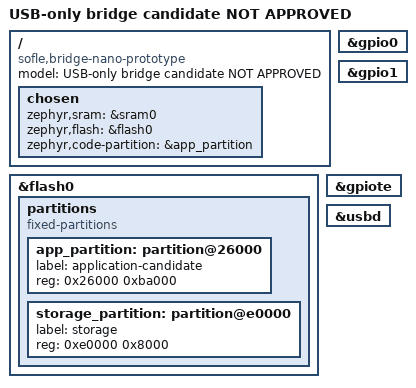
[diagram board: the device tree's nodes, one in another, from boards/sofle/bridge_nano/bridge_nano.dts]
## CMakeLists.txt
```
# Copyright (c) 2019 Nordic Semiconductor ASA
# SPDX-License-Identifier: LicenseRef-Nordic-5-Clause
cmake_minimum_required(VERSION 3.20.0)
set(BOARD_ROOT ${CMAKE_CURRENT_LIST_DIR})
find_package(Zephyr REQUIRED HINTS $ENV{ZEPHYR_BASE})
project(sofle_hogp_bridge)
target_sources(app PRIVATE src/main.c src/transport.c src/setup.c)
```

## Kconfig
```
# SPDX-License-Identifier: LicenseRef-Nordic-5-Clause
mainmenu "Sofle optional BLE HID host to USB bridge"
source "Kconfig.zephyr"
config BRIDGE_PHYSICAL_PAIRING
    bool "Unsupported physical pairing (negative-build safety gate only)"
    default n
    help
      No GPIO or reset button is assumed. Keep disabled. The USB vendor feature
      interface provides explicit scan/select/exact-target first pairing.
      Enabling physical pairing deliberately fails compilation even with alias.
config BRIDGE_AUTO_PAIR
    bool "Auto-pair to the exact keyboard name while the bond store is empty"
    default y
    help
      When the store has zero bonds, a connectable HID advertisement whose
      complete local name equals BRIDGE_PEER_NAME is connected and bonded
      automatically. The keyboard advertises this name only while a BT profile
      is in pairing mode, so first pairing needs no WebHID page. Any existing
      bond disables the path; re-pairing requires an explicit SETUP_UNBOND.
config BRIDGE_PEER_NAME
    string "Exact complete local name of the keyboard"
    default "Sofle_Oled"
    depends on BRIDGE_AUTO_PAIR
```

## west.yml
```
manifest:
  version: "0.13"
  projects:
    - name: nrf
      url: https://github.com/nrfconnect/sdk-nrf
      revision: 6961c01f95c2ec9f0f61870b68904bd398811f49 # NCS v2.9.3
      import:
        name-allowlist:
          - zephyr
          - cmsis
          - hal_nordic
          - segger
          - tinycrypt
          - nrfxlib
          - mbedtls
          - oberon-psa-crypto
          - zcbor
  self:
    path: bridge-manifest
```

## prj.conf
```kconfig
# Derived from roBa m1-hogp; SPDX-License-Identifier: LicenseRef-Nordic-5-Clause
CONFIG_BT=y
CONFIG_BT_CENTRAL=y
CONFIG_BT_CTLR=y
CONFIG_BT_LL_SOFTDEVICE=y
CONFIG_BT_SMP=y
CONFIG_BT_BONDABLE=n
CONFIG_BT_SMP_APP_PAIRING_ACCEPT=y
CONFIG_BT_GATT_CLIENT=y
CONFIG_BT_GATT_DM=y
CONFIG_BT_HOGP=y
CONFIG_BT_SCAN=y
CONFIG_BT_SCAN_FILTER_ENABLE=y
CONFIG_BT_SCAN_UUID_CNT=1
CONFIG_BT_PRIVACY=y
CONFIG_BT_SETTINGS=y
CONFIG_BT_MAX_CONN=1
CONFIG_BT_MAX_PAIRED=1
CONFIG_BT_KEYS_OVERWRITE_OLDEST=n
CONFIG_BT_ATT_TX_COUNT=5
CONFIG_BT_GATT_DM_MAX_ATTRS=100
CONFIG_BT_HOGP_REPORTS_MAX=8
# Peripheral-only auto-update Kconfig is inapplicable here; le_param_req accepts PPCP.
CONFIG_BT_GAP_AUTO_UPDATE_CONN_PARAMS=n
CONFIG_BT_USER_PHY_UPDATE=n
CONFIG_BT_AUTO_PHY_UPDATE=n
CONFIG_BT_DEVICE_NAME="Sofle optional HID bridge"
CONFIG_BT_CTLR_TX_PWR_PLUS_8=y
CONFIG_SYSTEM_WORKQUEUE_STACK_SIZE=4096
CONFIG_MAIN_STACK_SIZE=2048
CONFIG_HEAP_MEM_POOL_SIZE=4096
CONFIG_FLASH=y
CONFIG_FLASH_PAGE_LAYOUT=y
CONFIG_FLASH_MAP=y
CONFIG_NVS=y
CONFIG_SETTINGS=y
CONFIG_SETTINGS_NVS=y
CONFIG_USB_DEVICE_STACK=y
CONFIG_USB_COMPOSITE_DEVICE=y
CONFIG_USB_DEVICE_INITIALIZE_AT_BOOT=n
CONFIG_USB_DEVICE_HID=y
CONFIG_USB_HID_DEVICE_COUNT=2
CONFIG_ENABLE_HID_INT_OUT_EP=n
CONFIG_HID_INTERRUPT_EP_MPS=16
CONFIG_USB_HID_POLL_INTERVAL_MS=1
CONFIG_USB_HID_BOOT_PROTOCOL=n
CONFIG_USB_DEVICE_MANUFACTURER="Sofle bridge prototype"
CONFIG_USB_DEVICE_PRODUCT="Sofle BLE HID bridge NOT APPROVED"
CONFIG_USB_DEVICE_VID=0x2FE3
CONFIG_USB_DEVICE_PID=0x0100
CONFIG_USB_SELF_POWERED=n
CONFIG_LOG=n
CONFIG_BOOT_BANNER=n
CONFIG_NCS_BOOT_BANNER=n
CONFIG_PRINTK=n
CONFIG_CONSOLE=n
CONFIG_SERIAL=n
CONFIG_REBOOT=n
CONFIG_GPIO=y
CONFIG_USE_DT_CODE_PARTITION=y
CONFIG_BUILD_OUTPUT_HEX=y
CONFIG_BUILD_OUTPUT_BIN=y
CONFIG_BUILD_OUTPUT_UF2=n

# Auto-pairing to the keyboard while the bond store is empty.
CONFIG_BRIDGE_AUTO_PAIR=y
CONFIG_BRIDGE_PEER_NAME="Sofle_Oled"
```

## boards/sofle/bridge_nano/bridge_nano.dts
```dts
/* SPDX-License-Identifier: MIT
 * Compile-only candidate. NOT an approved flash layout. No UICR/regulator writes.
 * 0x26000 is the observed third-controller application's vector address.
 * Settings location is a NEW conservative candidate, not inferred from CURRENT.UF2.
 */
/dts-v1/;
#include <nordic/nrf52840_qiaa.dtsi>
/ {
    model = "USB-only bridge candidate NOT APPROVED";
    compatible = "sofle,bridge-nano-prototype";
    chosen {
        zephyr,sram = &sram0;
        zephyr,flash = &flash0;
        zephyr,code-partition = &app_partition;
    };
};
&flash0 {
    partitions {
        compatible = "fixed-partitions";
        #address-cells = <1>;
        #size-cells = <1>;
        app_partition: partition@26000 {
            label = "application-candidate";
            reg = <0x26000 0xba000>;
        };
        storage_partition: partition@e0000 {
            label = "storage";
            reg = <0xe0000 0x8000>;
        };
    };
};
&gpio0 { status = "okay"; };
&gpio1 { status = "okay"; };
&gpiote { status = "okay"; };
zephyr_udc0: &usbd { status = "okay"; };
```

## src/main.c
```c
/* main.c - adapted from hirosatosou/roba-ble-hid-bridge m1-hogp
 * Copyright (c) 2018 Nordic Semiconductor ASA
 * SPDX-License-Identifier: LicenseRef-Nordic-5-Clause
 * Nordic nRF52840 only. See UPSTREAM.md for provenance and deliberate removals.
 */
#include <errno.h>
#include <string.h>
#include <zephyr/kernel.h>
#include <zephyr/device.h>
#include <zephyr/drivers/gpio.h>
#include <zephyr/usb/usb_device.h>
#include <zephyr/usb/class/usb_hid.h>
#include <zephyr/bluetooth/bluetooth.h>
#include <zephyr/bluetooth/hci.h>
#include <zephyr/bluetooth/conn.h>
#include <zephyr/bluetooth/uuid.h>
#include <zephyr/bluetooth/gatt.h>
#include <zephyr/settings/settings.h>
#include <bluetooth/gatt_dm.h>
#include <bluetooth/scan.h>
#include <bluetooth/services/hogp.h>
#include "transport.h"
#include "setup.h"
#include "zmk_descriptor.h"

static struct bt_conn *default_conn;
static struct bt_hogp hogp;
static const struct device *hid_dev;
static struct bridge_queue queue;
static struct bridge_item in_flight; /* never alias a ring slot while USB owns it */
static bool ep_in_flight, usb_configured;
static atomic_t map_verified;
static struct k_spinlock hid_lock;
static struct setup_state setup;
static struct k_spinlock setup_lock;
static atomic_t conn_pending, have_bond, auto_pairing;
static bt_addr_le_t auto_target; /* exact-name auto-pair candidate in progress */
static bool auto_name_match; /* valid for the advertisement being processed */
static uint8_t feature_reply[SETUP_WIRE_SIZE];
static bool target_allowed(const bt_addr_le_t *addr) {
    k_spinlock_key_t key = k_spin_lock(&setup_lock);
    bool allowed = setup_target_allowed(&setup, k_uptime_get(), addr->type, addr->a.val);
    k_spin_unlock(&setup_lock, key);
    return allowed;
}
static void setup_end(void) {
    k_spinlock_key_t key = k_spin_lock(&setup_lock);
    setup_close(&setup);
    k_spin_unlock(&setup_lock, key);
    bt_set_bondable(false);
}
static size_t map_offset;
static uint8_t report_mask;

struct bond_lookup { const bt_addr_le_t *addr; bool found; };
static void bond_lookup_cb(const struct bt_bond_info *info, void *user_data) {
    struct bond_lookup *lookup = user_data;
    if (bt_addr_le_eq(&info->addr, lookup->addr)) lookup->found = true;
}
static bool is_bonded(const bt_addr_le_t *addr) {
    struct bond_lookup lookup = { .addr = addr };
    bt_foreach_bond(BT_ID_DEFAULT, bond_lookup_cb, &lookup);
    return lookup.found;
}
static void bond_count_cb(const struct bt_bond_info *info, void *user_data) {
    ARG_UNUSED(info); ++*(unsigned *)user_data;
}
static bool any_bond(void) {
    unsigned count = 0;
    bt_foreach_bond(BT_ID_DEFAULT, bond_count_cb, &count);
    return count != 0;
}
/* Called with hid_lock. A failed write keeps the item for periodic retry. */
static void hid_pump(void) {
    if (!usb_configured || ep_in_flight || queue.head == queue.tail) return;
    in_flight = queue.items[queue.tail];
    if (!hid_int_ep_write(hid_dev, in_flight.buf, in_flight.len, NULL)) {
        ep_in_flight = true;
        queue.tail = (queue.tail + 1) % BRIDGE_QUEUE_LEN;
    }
}
static void release_all(void) {
    k_spinlock_key_t key = k_spin_lock(&hid_lock);
    bridge_release_all(&queue);
    hid_pump();
    k_spin_unlock(&hid_lock, key);
}
static void hid_in_ready(const struct device *dev) {
    ARG_UNUSED(dev);
    k_spinlock_key_t key = k_spin_lock(&hid_lock);
    ep_in_flight = false;
    hid_pump();
    k_spin_unlock(&hid_lock, key);
}
static const struct hid_ops hid_ops = { .int_in_ready = hid_in_ready };
static void scan_restart(void);
static void unbond_work_fn(struct k_work *work) {
    ARG_UNUSED(work);
    (void)bt_unpair(BT_ID_DEFAULT, NULL); /* clear the whole store for this ID */
    atomic_clear(&have_bond);
    scan_restart(); /* bond store empty: auto-pair may run again */
}
static K_WORK_DEFINE(unbond_work, unbond_work_fn);
static int feature_set(const struct device *dev, struct usb_setup_packet *packet,
                       int32_t *len, uint8_t **data) {
    ARG_UNUSED(dev);
    if (!len || !data || *len < 0) return -EINVAL;
    k_spinlock_key_t key = k_spin_lock(&setup_lock);
    bool ok = setup_feature_set(&setup, k_uptime_get(), atomic_get(&conn_pending),
                               atomic_get(&have_bond), packet->wValue, packet->wLength,
                               *data, (size_t)*len);
    /* op byte sits at data[2]; SETUP_OK at reply[3]. The unpair itself is
     * deferred out of the USB callback context. */
    if (ok && (*data)[2] == SETUP_UNBOND && setup.reply[3] == SETUP_OK)
        k_work_submit(&unbond_work);
    k_spin_unlock(&setup_lock, key);
    return ok ? 0 : -EINVAL;
}
static int feature_get(const struct device *dev, struct usb_setup_packet *packet,
                       int32_t *len, uint8_t **data) {
    ARG_UNUSED(dev);
    if (!setup_feature_get_valid(packet->wValue, packet->wLength)) return -EINVAL;
    k_spinlock_key_t key = k_spin_lock(&setup_lock);
    memcpy(feature_reply, setup.reply, sizeof(feature_reply));
    k_spin_unlock(&setup_lock, key);
    *data = feature_reply; *len = sizeof(feature_reply);
    return 0;
}
static const struct hid_ops setup_ops = { .get_report = feature_get, .set_report = feature_set };
static void usb_status(enum usb_dc_status_code status, const uint8_t *param) {
    ARG_UNUSED(param);
    if (status == USB_DC_DISCONNECTED || status == USB_DC_RESET || status == USB_DC_SUSPEND) {
        k_spinlock_key_t sk = k_spin_lock(&setup_lock);
        setup_close(&setup); /* no pairing permission survives USB loss */
        k_spin_unlock(&setup_lock, sk);
    }
    k_spinlock_key_t key = k_spin_lock(&hid_lock);
    if (status == USB_DC_CONFIGURED) {
        usb_configured = true;
        ep_in_flight = false;
        bridge_release_all(&queue);
    } else if (status == USB_DC_DISCONNECTED || status == USB_DC_RESET) {
        usb_configured = false;
        ep_in_flight = false;
        bridge_release_all(&queue);
    }
    k_spin_unlock(&hid_lock, key);
}

static void scan_restart_work_fn(struct k_work *work) {
    ARG_UNUSED(work);
    if (default_conn) return;
    (void)bt_scan_stop();
    (void)bt_scan_start(BT_SCAN_TYPE_SCAN_ACTIVE);
}
static K_WORK_DELAYABLE_DEFINE(scan_restart_work, scan_restart_work_fn);
static void scan_restart(void) {
    k_work_reschedule(&scan_restart_work, K_SECONDS(1));
}
#if defined(CONFIG_BRIDGE_PHYSICAL_PAIRING)
/* Retain the negative build gate; no physical pairing path is implemented. */
BUILD_ASSERT(DT_NODE_HAS_STATUS(DT_ALIAS(bridge_pair), okay),
             "Verify physical wiring and define bridge-pair; never guess a GPIO");
BUILD_ASSERT(0, "Physical pairing unavailable: use explicit USB target selection");
#endif

/* Unlike upstream connect_if_match=1, unknown HID advertisements cannot create
 * connections outside an explicit window. Resolved bonded identity is allowed.
 */
static void try_connect(struct bt_scan_device_info *device_info, bool connectable) {
    if (!connectable || default_conn) return;
    const bt_addr_le_t *addr = device_info->recv_info->addr;
    bool bonded = is_bonded(addr);
    if (!bonded) {
        bool allowed = false;
        /* Auto-pair: ONLY when the store has zero bonds and the advertiser's
         * exact complete name equals CONFIG_BRIDGE_PEER_NAME. The keyboard
         * advertises this way only while a profile is in pairing mode, so a
         * bare dongle in a USB port pairs by plugging, with no WebHID page.
         * Any bond (even a foreign one) disables the path entirely. */
        if (IS_ENABLED(CONFIG_BRIDGE_AUTO_PAIR) && !any_bond() && auto_name_match) {
            atomic_set(&auto_pairing, 1);
            auto_target = *addr;
            allowed = true;
        } else {
            k_spinlock_key_t key = k_spin_lock(&setup_lock);
            allowed = setup_claim(&setup, k_uptime_get(), addr->type, addr->a.val);
            k_spin_unlock(&setup_lock, key);
        }
        if (!allowed) return;
        /* Set bondable before create/security, never from the USB callback. */
        bt_set_bondable(true);
    }
    if (bt_scan_stop()) {
        if (!bonded) { atomic_clear(&auto_pairing); setup_end(); }
        return;
    }
    atomic_set(&conn_pending, 1);
    struct bt_conn *conn = NULL;
    int err = bt_conn_le_create(device_info->recv_info->addr, BT_CONN_LE_CREATE_CONN,
                                BT_LE_CONN_PARAM(6, 24, 30, 400), &conn);
    if (!err) default_conn = conn; /* retain create's reference, released on disconnect */
    else { atomic_clear(&conn_pending); if (!bonded) { atomic_clear(&auto_pairing); setup_end(); } scan_restart(); }
}
static bool candidate_name(struct bt_data *data, void *user_data) {
    struct setup_peer *peer = user_data;
    if (data->type == BT_DATA_NAME_COMPLETE || data->type == BT_DATA_NAME_SHORTENED) {
        memcpy(peer->name, data->data, MIN(data->data_len, sizeof(peer->name) - 1));
        peer->name[sizeof(peer->name) - 1] = '\0';
        auto_name_match = IS_ENABLED(CONFIG_BRIDGE_AUTO_PAIR) &&
            strcmp(peer->name, CONFIG_BRIDGE_PEER_NAME) == 0;
        return false;
    }
    return true;
}
static void scan_filter_match(struct bt_scan_device_info *device_info,
                              struct bt_scan_filter_match *filter_match, bool connectable) {
    if (filter_match->uuid.match) {
        if (connectable) {
            struct setup_peer peer = { .type = device_info->recv_info->addr->type,
                                      .rssi = device_info->recv_info->rssi };
            memcpy(peer.addr, device_info->recv_info->addr->a.val, 6);
            auto_name_match = false;
            bt_data_parse(device_info->adv_data, candidate_name, &peer);
            k_spinlock_key_t key = k_spin_lock(&setup_lock);
            setup_observe(&setup, k_uptime_get(), &peer);
            k_spin_unlock(&setup_lock, key);
        }
        try_connect(device_info, connectable);
    }
}
static void scan_filter_no_match(struct bt_scan_device_info *device_info, bool connectable) {
    /* Directed reconnect often omits the HID service UUID. Bond check is mandatory. */
    if (device_info->recv_info->adv_type == BT_GAP_ADV_TYPE_ADV_DIRECT_IND &&
        is_bonded(device_info->recv_info->addr)) try_connect(device_info, connectable);
}
BT_SCAN_CB_INIT(scan_cb, scan_filter_match, scan_filter_no_match, NULL, NULL);
static int scan_init(void) {
    struct bt_scan_init_param init = { .connect_if_match = 0 };
    bt_scan_init(&init);
    bt_scan_cb_register(&scan_cb);
    int err = bt_scan_filter_add(BT_SCAN_FILTER_TYPE_UUID, BT_UUID_HIDS);
    if (err) return err;
    return bt_scan_filter_enable(BT_SCAN_UUID_FILTER, false);
}

static void discovery_completed_cb(struct bt_gatt_dm *dm, void *context) {
    ARG_UNUSED(context);
    int err = bt_hogp_handles_assign(dm, &hogp);
    (void)bt_gatt_dm_data_release(dm);
    if (err && default_conn)
        (void)bt_conn_disconnect(default_conn, BT_HCI_ERR_REMOTE_USER_TERM_CONN);
}
static void discovery_service_not_found_cb(struct bt_conn *conn, void *context) {
    ARG_UNUSED(context);
    (void)bt_conn_disconnect(conn, BT_HCI_ERR_REMOTE_USER_TERM_CONN);
}
static void discovery_error_found_cb(struct bt_conn *conn, int err, void *context) {
    ARG_UNUSED(err); discovery_service_not_found_cb(conn, context);
}
static const struct bt_gatt_dm_cb discovery_cb = {
    .completed = discovery_completed_cb,
    .service_not_found = discovery_service_not_found_cb,
    .error_found = discovery_error_found_cb,
};
static void connected(struct bt_conn *conn, uint8_t conn_err) {
    if (conn_err) {
        if (default_conn == conn) { bt_conn_unref(default_conn); default_conn = NULL; }
        atomic_clear(&conn_pending); setup_end(); scan_restart(); return;
    }
    if (!is_bonded(bt_conn_get_dst(conn)) && !target_allowed(bt_conn_get_dst(conn)) &&
        !(atomic_get(&auto_pairing) && bt_addr_le_eq(bt_conn_get_dst(conn), &auto_target))) {
        (void)bt_conn_disconnect(conn, BT_HCI_ERR_REMOTE_USER_TERM_CONN); return;
    }
    /* Do not force 2M; Sofle EXPERIMENTAL_CONN explicitly disables it.
     * Do not reject the keyboard's latency or keep reasserting min interval. */
    if (bt_conn_set_security(conn, BT_SECURITY_L2))
        (void)bt_conn_disconnect(conn, BT_HCI_ERR_AUTH_FAIL);
}
static void disconnected(struct bt_conn *conn, uint8_t reason) {
    ARG_UNUSED(reason);
    if (default_conn != conn) return;
    atomic_clear(&map_verified);
    release_all();
    if (bt_hogp_assign_check(&hogp)) bt_hogp_release(&hogp);
    bt_conn_unref(default_conn);
    default_conn = NULL;
    atomic_clear(&conn_pending); atomic_clear(&auto_pairing); setup_end();
    scan_restart(); /* keeps bonds; never unpair on RF/authentication failure */
}
static void security_changed(struct bt_conn *conn, bt_security_t level, enum bt_security_err err) {
    if (conn != default_conn) return;
    if (err || level < BT_SECURITY_L2 ||
        (!is_bonded(bt_conn_get_dst(conn)) && !target_allowed(bt_conn_get_dst(conn)))) {
        (void)bt_conn_disconnect(conn, BT_HCI_ERR_AUTH_FAIL); return;
    }
    if (bt_gatt_dm_start(conn, BT_UUID_HIDS, &discovery_cb, NULL))
        (void)bt_conn_disconnect(conn, BT_HCI_ERR_REMOTE_USER_TERM_CONN);
}
static bool le_param_req(struct bt_conn *conn, struct bt_le_conn_param *param) {
    ARG_UNUSED(conn); ARG_UNUSED(param);
    return true; /* let the controller validate spec bounds; accept Sofle PPCP */
}
BT_CONN_CB_DEFINE(conn_callbacks) = {
    .connected = connected, .disconnected = disconnected,
    .security_changed = security_changed, .le_param_req = le_param_req,
};
static enum bt_security_err pairing_accept(struct bt_conn *conn,
                                           const struct bt_conn_pairing_feat *feat) {
    ARG_UNUSED(feat);
    /* Existing bonds may encrypt/reconnect, but SMP re-pair/replacement is denied. */
    return conn == default_conn && !is_bonded(bt_conn_get_dst(conn)) &&
           (target_allowed(bt_conn_get_dst(conn)) ||
            (atomic_get(&auto_pairing) &&
             bt_addr_le_eq(bt_conn_get_dst(conn), &auto_target)))
        ? BT_SECURITY_ERR_SUCCESS : BT_SECURITY_ERR_PAIR_NOT_ALLOWED;
}
static const struct bt_conn_auth_cb auth_callbacks = { .pairing_accept = pairing_accept };
static void pairing_complete(struct bt_conn *conn, bool bonded) {
    if (!bonded) { (void)bt_conn_disconnect(conn, BT_HCI_ERR_AUTH_FAIL); return; }
    atomic_set(&have_bond, 1);
    atomic_clear(&auto_pairing);
    setup_end();
}
static struct bt_conn_auth_info_cb auth_info = { .pairing_complete = pairing_complete };

static uint8_t hogp_notify_cb(struct bt_hogp *client, struct bt_hogp_rep_info *rep,
                              uint8_t err, const uint8_t *data) {
    ARG_UNUSED(client);
    if (!data) return BT_GATT_ITER_STOP;
    if (err || !atomic_get(&map_verified)) return BT_GATT_ITER_CONTINUE;
    struct bridge_item item;
    /* Report Reference determines ID and TYPE; NOT enumeration order/handle.
     * Only the body is provided by HOGP; append exactly one USB report ID. */
    if (!bridge_convert(&item, bt_hogp_rep_id(rep), bt_hogp_rep_type(rep),
                        data, bt_hogp_rep_size(rep))) return BT_GATT_ITER_CONTINUE;
    k_spinlock_key_t key = k_spin_lock(&hid_lock);
    (void)bridge_enqueue(&queue, &item);
    hid_pump();
    k_spin_unlock(&hid_lock, key);
    return BT_GATT_ITER_CONTINUE;
}
static void subscribe_work_fn(struct k_work *work) {
    ARG_UNUSED(work);
    if (!default_conn || !bt_hogp_assign_check(&hogp) || !atomic_get(&map_verified)) return;
    struct bt_hogp_rep_info *rep = NULL;
    report_mask = 0;
    while ((rep = bt_hogp_rep_next(&hogp, rep))) {
        uint8_t id = bt_hogp_rep_id(rep);
        if (bt_hogp_rep_type(rep) != BT_HIDS_REPORT_TYPE_INPUT) continue;
        if (!bridge_body_size(id) || (report_mask & BIT(id))) goto fail;
        report_mask |= BIT(id);
        if (bt_hogp_rep_subscribe(&hogp, rep, hogp_notify_cb)) goto fail;
    }
    if (report_mask != (BIT(1) | BIT(2) | BIT(3))) goto fail;
    return;
fail:
    atomic_clear(&map_verified);
    release_all();
    (void)bt_conn_disconnect(default_conn, BT_HCI_ERR_REMOTE_USER_TERM_CONN);
}
static K_WORK_DEFINE(subscribe_work, subscribe_work_fn);
static void hogp_map_check_cb(struct bt_hogp *client, uint8_t err,
                              const uint8_t *data, size_t size, size_t offset) {
    if (!default_conn) return;
    if (err || offset != map_offset) goto fail;
    if (!data || !size) {
        if (map_offset != sizeof(bridge_report_desc)) goto fail;
        atomic_set(&map_verified, 1);
        k_work_submit(&subscribe_work);
        return;
    }
    if (offset > sizeof(bridge_report_desc) || size > sizeof(bridge_report_desc) - offset ||
        memcmp(data, bridge_report_desc + offset, size)) goto fail;
    map_offset += size;
    if (bt_hogp_map_read(client, hogp_map_check_cb, map_offset, K_NO_WAIT)) goto fail;
    return;
fail:
    atomic_clear(&map_verified);
    (void)bt_conn_disconnect(default_conn, BT_HCI_ERR_REMOTE_USER_TERM_CONN);
}
static void hids_ready_work_fn(struct k_work *work) {
    ARG_UNUSED(work);
    if (!default_conn || !bt_hogp_assign_check(&hogp)) return;
    atomic_clear(&map_verified);
    map_offset = 0;
    if (bt_hogp_map_read(&hogp, hogp_map_check_cb, 0, K_NO_WAIT))
        (void)bt_conn_disconnect(default_conn, BT_HCI_ERR_REMOTE_USER_TERM_CONN);
}
static K_WORK_DEFINE(hids_ready_work, hids_ready_work_fn);
static void hogp_ready_cb(struct bt_hogp *client) {
    ARG_UNUSED(client); k_work_submit(&hids_ready_work);
}
static void hogp_prep_fail_cb(struct bt_hogp *client, int err) {
    ARG_UNUSED(client); ARG_UNUSED(err);
    if (default_conn) (void)bt_conn_disconnect(default_conn, BT_HCI_ERR_REMOTE_USER_TERM_CONN);
}
static const struct bt_hogp_init_params hogp_init_params = {
    .ready_cb = hogp_ready_cb, .prep_error_cb = hogp_prep_fail_cb,
};
static void expire_connection(struct bt_conn *conn, void *user_data) {
    ARG_UNUSED(user_data);
    /* bt_conn_foreach owns a temporary reference; don't dereference a racing
     * default_conn from the main thread while the RX callback can unref it. */
    if (!is_bonded(bt_conn_get_dst(conn)) && !target_allowed(bt_conn_get_dst(conn)))
        (void)bt_conn_disconnect(conn, BT_HCI_ERR_REMOTE_USER_TERM_CONN);
}
static void count_bond(const struct bt_bond_info *info, void *user_data) {
    ARG_UNUSED(info); ARG_UNUSED(user_data); atomic_set(&have_bond, 1);
}
int main(void) {
    bt_hogp_init(&hogp, &hogp_init_params);
    int err = bt_conn_auth_cb_register(&auth_callbacks);
    if (err) return err;
    err = bt_conn_auth_info_cb_register(&auth_info);
    if (err) return err;
    err = bt_enable(NULL); /* retain upstream's BT-before-USB ordering */
    if (err) return err;
    err = settings_load();
    if (err) return err;
    bt_set_bondable(false); /* NO auto-pairing on empty NVS, errors or reboots */
    bt_foreach_bond(BT_ID_DEFAULT, count_bond, NULL);
    hid_dev = device_get_binding("HID_0");
    if (!hid_dev) return -ENODEV;
    usb_hid_register_device(hid_dev, bridge_report_desc, sizeof(bridge_report_desc), &hid_ops);
    err = usb_hid_init(hid_dev);
    if (err) return err;
    const struct device *setup_dev = device_get_binding("HID_1");
    if (!setup_dev) return -ENODEV;
    usb_hid_register_device(setup_dev, setup_report_desc, sizeof(setup_report_desc), &setup_ops);
    err = usb_hid_init(setup_dev);
    if (err) return err;
    err = usb_enable(usb_status);
    if (err) return err;
    err = scan_init();
    if (err) return err;

    scan_restart();
    while (1) {
        k_spinlock_key_t sk = k_spin_lock(&setup_lock);
        setup_expire(&setup, k_uptime_get());
        bool armed = setup.pair_until != 0 || atomic_get(&auto_pairing);
        k_spin_unlock(&setup_lock, sk);
        if (!armed) {
            bt_set_bondable(false);
            bt_conn_foreach(BT_CONN_TYPE_LE, expire_connection, NULL);
        }
        k_spinlock_key_t key = k_spin_lock(&hid_lock);
        hid_pump(); /* retries USB busy/not-ready; no new input required */
        k_spin_unlock(&hid_lock, key);
        k_msleep(1);
    }
    return 0;
}
```

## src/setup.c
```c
/* SPDX-License-Identifier: MIT */
#include "setup.h"
#include <string.h>
/* Separate HID interface: vendor page FF31, usage 74. No keyboard/mouse TLC,
 * no shared report IDs, no input/output reports, no Studio RPC transport. */
const uint8_t setup_report_desc[23] = {
    0x06,0x31,0xff, 0x09,0x74, 0xa1,0x01, 0x85,SETUP_REPORT_ID,
    0x15,0x00, 0x26,0xff,0x00, 0x75,0x08, 0x95,SETUP_BODY_SIZE,
    0x09,0x75, 0xb1,0x02, 0xc0
};
static bool address_valid(uint8_t type, const uint8_t *addr) {
    if (type > 1) return false; /* no ANY, identity aliases, wildcard or unspecified */
    unsigned zeros=0, ones=0;
    for (unsigned i=0; i<6; ++i) { zeros += addr[i]==0; ones += addr[i]==255; }
    return zeros != 6 && ones != 6;
}
static bool same(const struct setup_peer *p, uint8_t type, const uint8_t *addr) {
    return p->type == type && !memcmp(p->addr, addr, 6);
}
void setup_close(struct setup_state *s) {
    s->scan_until = s->pair_until = 0;
    s->selected = s->claimed = false;
    memset(&s->target, 0, sizeof(s->target));
}
void setup_expire(struct setup_state *s, uint64_t now) {
    if (s->scan_until && now >= s->scan_until) {
        s->scan_until = 0;
        if (!s->pair_until) s->selected = false;
    }
    if (s->pair_until && now >= s->pair_until) setup_close(s);
}
void setup_observe(struct setup_state *s, uint64_t now, const struct setup_peer *p) {
    if (!s->scan_until || now >= s->scan_until || !address_valid(p->type,p->addr)) return;
    unsigned i;
    for (i=0; i<s->count; ++i) if (same(&s->peers[i],p->type,p->addr)) break;
    if (i==s->count) {
        if (s->count == SETUP_MAX_CANDIDATES) return;
        ++s->count;
    }
    s->peers[i] = *p;
    /* Names are untrusted advertisements, not an identity/authentication claim. */
    for (unsigned j=0;j<sizeof(p->name);++j)
        if ((unsigned char)s->peers[i].name[j] < 32 || (unsigned char)s->peers[i].name[j] > 126)
            s->peers[i].name[j] = ' ';
}
bool setup_target_allowed(const struct setup_state *s, uint64_t now, uint8_t type, const uint8_t addr[6]) {
    return s->selected && s->pair_until && now < s->pair_until && same(&s->target,type,addr);
}
bool setup_claim(struct setup_state *s, uint64_t now, uint8_t type, const uint8_t addr[6]) {
    if (s->claimed || !setup_target_allowed(s,now,type,addr)) return false;
    s->claimed = true; /* one connection attempt per explicit ARM */
    return true;
}
static void reply(struct setup_state *s, uint8_t op, uint8_t status, uint8_t index,
                  const struct setup_peer *peer) {
    memset(s->reply,0,sizeof(s->reply));
    s->reply[0] = SETUP_REPORT_ID;
    uint8_t *r = s->reply+1;
    r[0]=SETUP_VERSION; r[1]=op; r[2]=status;
    r[3]=(s->scan_until ? 1:0) | (s->selected ? 2:0) | (s->pair_until ? 4:0) | (s->claimed ? 8:0);
    r[4]=index; r[5]=s->count;
    if (peer) {
        r[6]=peer->type; memcpy(r+7,peer->addr,6); r[13]=(uint8_t)peer->rssi;
        memcpy(r+14,peer->name,18);
    }
}
bool setup_feature_get_valid(uint16_t value, uint16_t requested) {
    return value == (0x0300 | SETUP_REPORT_ID) && requested == SETUP_WIRE_SIZE;
}
bool setup_feature_set(struct setup_state *s, uint64_t now, bool connected, bool bonded,
                       uint16_t value, uint16_t requested, const uint8_t *data, size_t len) {
    if (!setup_feature_get_valid(value,requested) || len != SETUP_WIRE_SIZE ||
        !data || data[0] != SETUP_REPORT_ID) return false;
    setup_expire(s,now);
    const uint8_t *c=data+1;
    uint8_t op=c[1], status=SETUP_OK, index=c[2];
    const struct setup_peer *peer=NULL;
    bool target_op=op==SETUP_SELECT || op==SETUP_ARM;
    bool valid=c[0]==SETUP_VERSION && op>=SETUP_SCAN && op<=SETUP_UNBOND;
    for (unsigned i=10;i<SETUP_BODY_SIZE;++i) if(c[i]) valid=false;
    if (op!=SETUP_READ && index) valid=false;
    if (target_op) { if (!address_valid(c[3],c+4)) valid=false; }
    else { for(unsigned i=3;i<10;++i) if(c[i]) valid=false; }
    if (!valid) status=SETUP_INVALID;
    else if (op==SETUP_STATUS) peer=s->selected ? &s->target : NULL;
    else if (op==SETUP_READ) {
        if(index>=s->count) status=SETUP_NOT_SEEN;
        else peer=&s->peers[index];
    } else if (connected || s->pair_until) status=SETUP_BUSY;
    else if (op==SETUP_SCAN) {
        setup_close(s); s->count=0; s->scan_until=now+SETUP_SCAN_MS;
    } else if (op==SETUP_UNBOND) {
        /* Clearing the store is explicit, never implicit; the caller performs
         * the Bluetooth unpair outside this pure-logic module. */
        setup_close(s); status=SETUP_OK;
    } else if (bonded) status=SETUP_BONDED; /* no replacement, no overwrite */
    else if (!s->scan_until) status=SETUP_EXPIRED;
    else if (op==SETUP_SELECT) {
        unsigned i;
        for(i=0;i<s->count;++i) if(same(&s->peers[i],c[3],c+4)) break;
        if(i==s->count) status=SETUP_NOT_SEEN;
        else { s->target=s->peers[i]; s->selected=true; peer=&s->target; }
    } else if (op==SETUP_ARM) {
        if(!s->selected || !same(&s->target,c[3],c+4)) status=SETUP_NOT_SELECTED;
        else { s->pair_until=now+SETUP_PAIR_MS; s->scan_until=0; s->claimed=false; peer=&s->target; }
    }
    reply(s,op,status,index,peer);
    s->reply[4] |= (bonded ? 16:0) | (connected ? 32:0);
    return true;
}
```

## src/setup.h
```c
/* SPDX-License-Identifier: MIT */
#pragma once
#include <stdbool.h>
#include <stddef.h>
#include <stdint.h>
#define SETUP_REPORT_ID 0x40
#define SETUP_BODY_SIZE 32
#define SETUP_WIRE_SIZE 33
#define SETUP_VERSION 1
#define SETUP_MAX_CANDIDATES 16
#define SETUP_SCAN_MS 30000
#define SETUP_PAIR_MS 20000
/* Fixed wire schema documented in ../PAIRING.md. Addresses are BLE little endian. */
enum setup_op { SETUP_SCAN=1, SETUP_READ=2, SETUP_SELECT=3, SETUP_ARM=4, SETUP_STATUS=5,
                SETUP_UNBOND=6 };
enum setup_status { SETUP_OK, SETUP_INVALID, SETUP_BUSY, SETUP_EXPIRED, SETUP_NOT_SEEN, SETUP_NOT_SELECTED, SETUP_BONDED };
struct setup_peer { uint8_t type, addr[6]; int8_t rssi; char name[18]; };
struct setup_state {
    struct setup_peer peers[SETUP_MAX_CANDIDATES], target;
    uint8_t count;
    bool selected, claimed;
    uint64_t scan_until, pair_until;
    uint8_t reply[SETUP_WIRE_SIZE];
};
extern const uint8_t setup_report_desc[23];
void setup_expire(struct setup_state *s, uint64_t now);
void setup_close(struct setup_state *s);
void setup_observe(struct setup_state *s, uint64_t now, const struct setup_peer *p);
bool setup_target_allowed(const struct setup_state *s, uint64_t now, uint8_t type, const uint8_t addr[6]);
bool setup_claim(struct setup_state *s, uint64_t now, uint8_t type, const uint8_t addr[6]);
/* Returns false for malformed USB envelope (STALL); protocol errors are replies.
 * No Bluetooth, storage, reset, input payload or Studio operations exist here. */
bool setup_feature_set(struct setup_state *s, uint64_t now, bool connected, bool bonded,
                       uint16_t value, uint16_t requested, const uint8_t *data, size_t len);
bool setup_feature_get_valid(uint16_t value, uint16_t requested);
```

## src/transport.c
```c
/* Derived from roBa bridge serializer; Copyright (c) 2018 Nordic Semiconductor ASA
 * SPDX-License-Identifier: LicenseRef-Nordic-5-Clause */
#include "transport.h"
#include <string.h>
size_t bridge_body_size(uint8_t id) {
    switch (id) { case 1: return 8; case 2: return 6; case 3: return 9; default: return 0; }
}
bool bridge_convert(struct bridge_item *out, uint8_t id, uint8_t type,
                    const uint8_t *body, size_t size) {
    size_t expected = bridge_body_size(id);
    if (!out || !body || type != 1 || !expected || size != expected) return false;
    memset(out, 0, sizeof(*out));
    out->len = (uint8_t)(size + 1);
    out->buf[0] = id; /* BLE characteristic body has NO ID; USB has exactly one ID. */
    memcpy(out->buf + 1, body, size);
    return true;
}
bool bridge_pop(struct bridge_queue *q, struct bridge_item *item) {
    if (q->head == q->tail) return false;
    *item = q->items[q->tail];
    q->tail = (q->tail + 1) % BRIDGE_QUEUE_LEN;
    return true;
}
void bridge_release_all(struct bridge_queue *q) {
    /* Purge stale presses and deltas; keep the separately owned in-flight USB buffer. */
    q->head = q->tail = 0;
    for (uint8_t id = 1; id <= 3; ++id) {
        struct bridge_item item = { .len = (uint8_t)(bridge_body_size(id) + 1), .buf = { id } };
        q->items[q->head++] = item;
    }
}
bool bridge_enqueue(struct bridge_queue *q, const struct bridge_item *item) {
    if (!item || item->len < 2 || item->len > sizeof(item->buf)) return false;
    uint8_t next = (q->head + 1) % BRIDGE_QUEUE_LEN;
    if (next == q->tail) {
        q->overflows++;
        bridge_release_all(q); /* fail neutral, never silently lose the last key-up */
        return false;
    }
    q->items[q->head] = *item;
    q->head = next;
    return true;
}
```

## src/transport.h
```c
/* Derived from roBa bridge serializer; Copyright (c) 2018 Nordic Semiconductor ASA
 * SPDX-License-Identifier: LicenseRef-Nordic-5-Clause */
#pragma once
#include <stdbool.h>
#include <stddef.h>
#include <stdint.h>
#define BRIDGE_QUEUE_LEN 32
struct bridge_item { uint8_t len; uint8_t buf[10]; };
struct bridge_queue {
    struct bridge_item items[BRIDGE_QUEUE_LEN];
    uint8_t head, tail;
    uint32_t overflows;
};
size_t bridge_body_size(uint8_t report_id);
bool bridge_convert(struct bridge_item *out, uint8_t report_id, uint8_t report_type,
                    const uint8_t *body, size_t size);
void bridge_release_all(struct bridge_queue *q);
bool bridge_enqueue(struct bridge_queue *q, const struct bridge_item *item);
bool bridge_pop(struct bridge_queue *q, struct bridge_item *item);
```

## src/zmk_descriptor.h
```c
/* Generated from ZMK hid.h; Copyright (c) 2020 The ZMK Contributors
 * SPDX-License-Identifier: MIT
 * Run tools/derive_descriptor.py with the pinned core to reproduce. */
#pragma once
#include <stdint.h>
static const uint8_t bridge_report_desc[] = {
    0x05, 0x01, 0x09, 0x06, 0xa1, 0x01, 0x85, 0x01, 0x05, 0x07, 0x19, 0xe0, 0x29, 0xe7, 0x15, 0x00,
    0x25, 0x01, 0x75, 0x01, 0x95, 0x08, 0x81, 0x02, 0x05, 0x07, 0x75, 0x08, 0x95, 0x01, 0x81, 0x03,
    0x05, 0x07, 0x15, 0x00, 0x26, 0xff, 0x00, 0x19, 0x00, 0x29, 0xff, 0x75, 0x08, 0x95, 0x06, 0x81,
    0x00, 0xc0, 0x05, 0x0c, 0x09, 0x01, 0xa1, 0x01, 0x85, 0x02, 0x05, 0x0c, 0x15, 0x00, 0x26, 0xff,
    0x00, 0x19, 0x00, 0x29, 0xff, 0x75, 0x08, 0x95, 0x06, 0x81, 0x00, 0xc0, 0x05, 0x01, 0x09, 0x02,
    0xa1, 0x01, 0x85, 0x03, 0x09, 0x01, 0xa1, 0x00, 0x05, 0x09, 0x19, 0x01, 0x29, 0x05, 0x15, 0x00,
    0x25, 0x01, 0x75, 0x01, 0x95, 0x05, 0x81, 0x02, 0x75, 0x03, 0x95, 0x01, 0x81, 0x03, 0x05, 0x01,
    0x09, 0x30, 0x09, 0x31, 0x16, 0x00, 0x80, 0x26, 0xff, 0x7f, 0x75, 0x10, 0x95, 0x02, 0x81, 0x06,
    0xa1, 0x02, 0x09, 0x38, 0x16, 0x00, 0x80, 0x26, 0xff, 0x7f, 0x35, 0x00, 0x45, 0x00, 0x75, 0x10,
    0x95, 0x01, 0x81, 0x06, 0xc0, 0xa1, 0x02, 0x05, 0x0c, 0x0a, 0x38, 0x02, 0x16, 0x00, 0x80, 0x26,
    0xff, 0x7f, 0x35, 0x00, 0x45, 0x00, 0x75, 0x10, 0x95, 0x01, 0x81, 0x06, 0xc0, 0xc0, 0xc0,
};
```
